# CY8C4245AXI_483 register map
File version: 0.1
PSoC 4200
Registers are 32-bit, read-write, no defined reset value unless marked. A register's access mark holds for its fields unless they carry their own. Offsets are from the block's base; lines under a group give offsets from that group; [hi:lo] are bit positions; {n}, {i} and the like mark numbered series; 'fields as' and 'values as' point back to an identical list; <NAME> marks a mode.

## Memory map
0x00000000 DISPLAY_UART — UART
0x00000000 PRIME_UART — Serial Communication Block
0x00000000 ADC — Sequencing SAR ADC
0x00000000 STACK_I2C — Serial Communication Block
0x00000000 PWM_RED_WHITE
0x00000000 PWM_BLUE_FAN
0x00000000 CONTROL_LOOP_TIMER

## DISPLAY_UART — UART
Base 0x00000000
0x400F0042 TX_DISPLAY_UART_TX_DATA 8-bit — TX Data Register
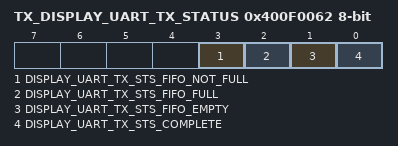
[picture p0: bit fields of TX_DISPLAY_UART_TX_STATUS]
0x400F0062 TX_DISPLAY_UART_TX_STATUS 8-bit — TX status register
  [3] DISPLAY_UART_TX_STS_FIFO_NOT_FULL ro, [2] DISPLAY_UART_TX_STS_FIFO_FULL ro, [1] DISPLAY_UART_TX_STS_FIFO_EMPTY ro, [0] DISPLAY_UART_TX_STS_COMPLETE ro

## PWM_RED_WHITE
Base 0x00000000
0x400F0020 PWM_RED_WHITE__COMPARE1 8-bit — UDB.D0 - Assigned Compare1 Value
0x400F0030 PWM_RED_WHITE__COMPARE2 8-bit — UDB.D1 - Assigned Compare2 Value
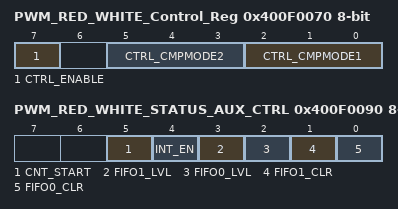
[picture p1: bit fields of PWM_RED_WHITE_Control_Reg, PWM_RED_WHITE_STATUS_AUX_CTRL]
0x400F0070 PWM_RED_WHITE_Control_Reg 8-bit — UDB Control Register - Assigned Control Register Value
  [7] CTRL_ENABLE — Enable the PWM
  [5:3] CTRL_CMPMODE2 — Compare mode 2
  [2:0] CTRL_CMPMODE1 — Compare mode 1
0x400F0090 PWM_RED_WHITE_STATUS_AUX_CTRL 8-bit — UDB Auxilliary Control Register
  [5] CNT_START — FIFO0 clear
    0=E_CNT_START0 (Disable counter); 1=E_CNT_START1 (Enable counter)
  [4] INT_EN
    0=E_INT_EN0 (Interrupt disabled); 1=E_INT_EN1 (Interrupt enabled)
  [3] FIFO1_LVL — FIFO level
    0=E_FIFO_LVL_0 (FIFO LVL: input mode: FIFO not full; output mode: FIFO not empty); 1=E_FIFO_LVL_1 (FIFO LVL: input mode: FIFO at least 1/2 empty; output mode: FIFO at least 1/2 full)
  [2] FIFO0_LVL — FIFO level
    values as FIFO1_LVL
  [1] FIFO1_CLR — FIFO1 clear
    0=E_FIFO_CLR_0 (Normal FIFO operation); 1=E_FIFO_CLR_1 (Clear FIFO state)
  [0] FIFO0_CLR — FIFO0 clear
    values as FIFO1_CLR

## PWM_BLUE_FAN
Base 0x00000000
0x400F0021 PWM_BLUE_FAN__COMPARE1 8-bit — UDB.D0 - Assigned Compare1 Value
0x400F0031 PWM_BLUE_FAN__COMPARE2 8-bit — UDB.D1 - Assigned Compare2 Value
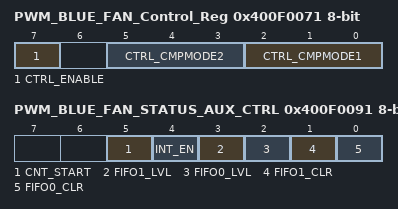
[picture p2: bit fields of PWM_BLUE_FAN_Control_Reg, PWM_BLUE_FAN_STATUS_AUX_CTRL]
0x400F0071 PWM_BLUE_FAN_Control_Reg 8-bit — UDB Control Register - Assigned Control Register Value
  [7] CTRL_ENABLE — Enable the PWM
  [5:3] CTRL_CMPMODE2 — Compare mode 2
  [2:0] CTRL_CMPMODE1 — Compare mode 1
0x400F0091 PWM_BLUE_FAN_STATUS_AUX_CTRL 8-bit — UDB Auxilliary Control Register
  [5] CNT_START — FIFO0 clear
    0=E_CNT_START0 (Disable counter); 1=E_CNT_START1 (Enable counter)
  [4] INT_EN
    0=E_INT_EN0 (Interrupt disabled); 1=E_INT_EN1 (Interrupt enabled)
  [3] FIFO1_LVL — FIFO level
    0=E_FIFO_LVL_0 (FIFO LVL: input mode: FIFO not full; output mode: FIFO not empty); 1=E_FIFO_LVL_1 (FIFO LVL: input mode: FIFO at least 1/2 empty; output mode: FIFO at least 1/2 full)
  [2] FIFO0_LVL — FIFO level
    values as FIFO1_LVL
  [1] FIFO1_CLR — FIFO1 clear
    0=E_FIFO_CLR_0 (Normal FIFO operation); 1=E_FIFO_CLR_1 (Clear FIFO state)
  [0] FIFO0_CLR — FIFO0 clear
    values as FIFO1_CLR

## CONTROL_LOOP_TIMER
Base 0x00000000
0x40050108 COUNTER — Current counter value
0x4005010C CC — Compare / capture value
0x40050110 CC_BUF — Compare / capture buffer value
0x40050114 PERIOD — Period value
0x40050118 PERIOD_BUF — Period buffer value
